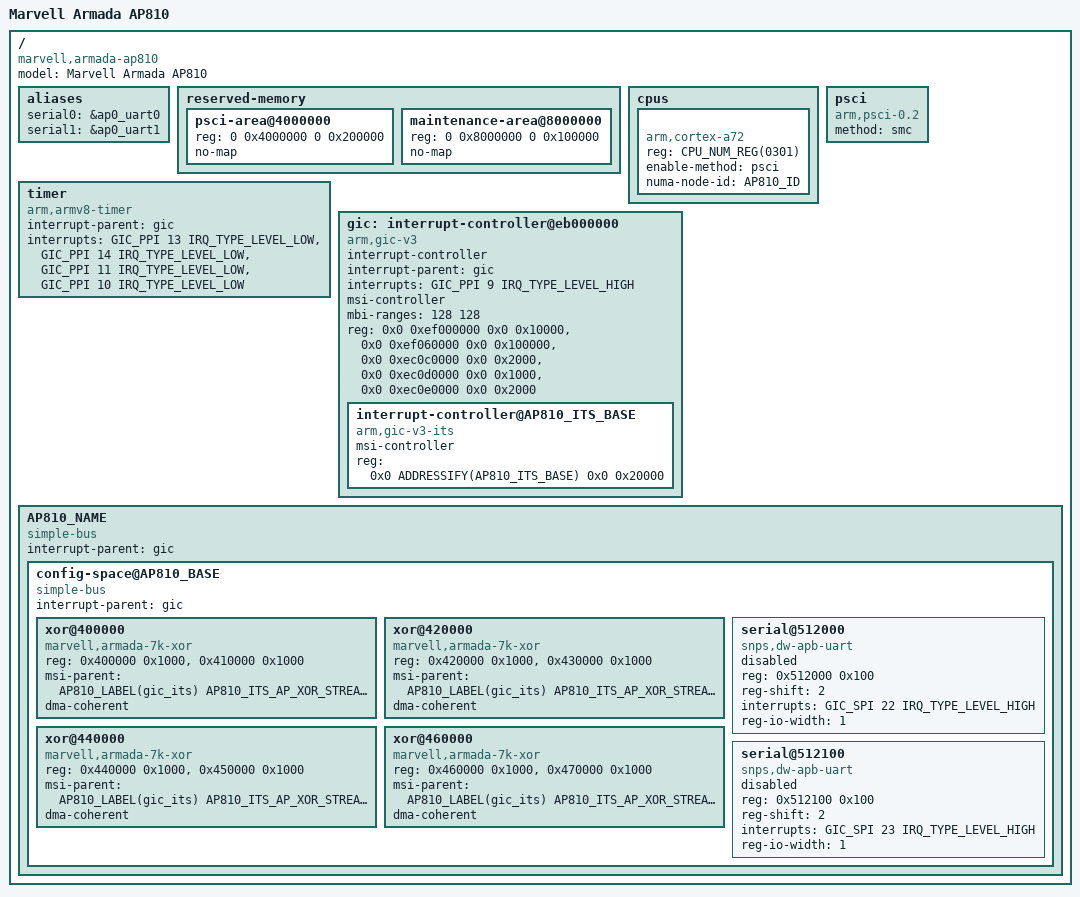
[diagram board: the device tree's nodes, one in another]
// SPDX-License-Identifier: (GPL-2.0+ OR MIT)
/*
 * Copyright (C) 2017 Marvell Technology Group Ltd.
 *
 * Device Tree file for Marvell Armada AP810.
 *
 * To include this file, the following definitions must exist:
 *  - AP810_ID:       number of the AP
 *  - AP810_NAME:     provided by armada-common.dtsi based on AP810_ID
 *  - AP810_LABEL:    provided by armada-common.dtsi based on AP810_ID
 *  - AP810_BASE:     base address of registers for this AP
 *                    (without leading 0x)
 *  - AP810_ITS_BASE: base address of the ITS for this AP
 *                    (without leading 0x)
 */

#include <dt-bindings/interrupt-controller/arm-gic.h>

#define CPU_NUM(x)	EVALUATOR(AP810_ID, x)
#define CPU_NUM_REG(x)	ADDRESSIFY(CPU_NUM(x))

#define AP810_ITS_AP_XOR_STREAM_ID(x)	(0x200 * AP810_ID + 0x100 + (x))

/ {
	model = "Marvell Armada AP810";
	compatible = "marvell,armada-ap810";
	#address-cells = <2>;
	#size-cells = <2>;

	aliases {
		serial0 = &ap0_uart0;
		serial1 = &ap0_uart1;
	};

        reserved-memory {
                #address-cells = <2>;
                #size-cells = <2>;
                ranges;

                psci-area@4000000 {
                        reg = <0 0x4000000 0 0x200000>;
                        no-map;
                };

                maintenance-area@8000000 {
                        reg = <0 0x8000000 0 0x100000>;
                        no-map;
                };
        };

	cpus {
		#address-cells = <1>;
		#size-cells = <0>;

		cpu@CPU_NUM(0000) {
			device_type = "cpu";
			compatible = "arm,cortex-a72", "arm,armv8";
			reg = <CPU_NUM_REG(0000)>;
			enable-method = "psci";
			numa-node-id = <AP810_ID>;
		};
		cpu@CPU_NUM(0001) {
			device_type = "cpu";
			compatible = "arm,cortex-a72", "arm,armv8";
			reg = <CPU_NUM_REG(0001)>;
			enable-method = "psci";
			numa-node-id = <AP810_ID>;
		};
		cpu@CPU_NUM(0100) {
			device_type = "cpu";
			compatible = "arm,cortex-a72", "arm,armv8";
			reg = <CPU_NUM_REG(0100)>;
			enable-method = "psci";
			numa-node-id = <AP810_ID>;
		};
		cpu@CPU_NUM(0101) {
			device_type = "cpu";
			compatible = "arm,cortex-a72", "arm,armv8";
			reg = <CPU_NUM_REG(0101)>;
			enable-method = "psci";
			numa-node-id = <AP810_ID>;
		};
		cpu@CPU_NUM(0200) {
			device_type = "cpu";
			compatible = "arm,cortex-a72", "arm,armv8";
			reg = <CPU_NUM_REG(0200)>;
			enable-method = "psci";
			numa-node-id = <AP810_ID>;
		};
		cpu@CPU_NUM(0201) {
			device_type = "cpu";
			compatible = "arm,cortex-a72", "arm,armv8";
			reg = <CPU_NUM_REG(0201)>;
			enable-method = "psci";
			numa-node-id = <AP810_ID>;
		};
		cpu@CPU_NUM(0300) {
			device_type = "cpu";
			compatible = "arm,cortex-a72", "arm,armv8";
			reg = <CPU_NUM_REG(0300)>;
			enable-method = "psci";
			numa-node-id = <AP810_ID>;
		};
		cpu@CPU_NUM(0301) {
			device_type = "cpu";
			compatible = "arm,cortex-a72", "arm,armv8";
			reg = <CPU_NUM_REG(0301)>;
			enable-method = "psci";
			numa-node-id = <AP810_ID>;
		};
	};

	psci {
		compatible = "arm,psci-0.2";
		method = "smc";
	};

	timer {
		compatible = "arm,armv8-timer";
		interrupt-parent = <&gic>;
		interrupts = <GIC_PPI 13 IRQ_TYPE_LEVEL_LOW>,
			     <GIC_PPI 14 IRQ_TYPE_LEVEL_LOW>,
			     <GIC_PPI 11 IRQ_TYPE_LEVEL_LOW>,
			     <GIC_PPI 10 IRQ_TYPE_LEVEL_LOW>;
	};

	gic: interrupt-controller@eb000000 {
		compatible = "arm,gic-v3";
		#interrupt-cells = <3>;
		#address-cells = <2>;
		#size-cells = <2>;
		interrupt-controller;
		interrupt-parent = <&gic>;
		interrupts = <GIC_PPI 9 IRQ_TYPE_LEVEL_HIGH>;
		msi-controller;
		mbi-ranges = <128 128>; /* FIXME */
		ranges;

		reg = <0x0 0xef000000 0x0 0x10000>,	/* GICD */
		      <0x0 0xef060000 0x0 0x100000>,	/* GICR */
		      <0x0 0xec0c0000 0x0 0x2000>,	/* GICC */
		      <0x0 0xec0d0000 0x0 0x1000>,	/* GICH */
		      <0x0 0xec0e0000 0x0 0x2000>;	/* GICV */

		AP810_LABEL(gic_its): interrupt-controller@AP810_ITS_BASE {
			compatible = "arm,gic-v3-its";
			msi-controller;
			#msi-cells = <1>;
			reg = <0x0 ADDRESSIFY(AP810_ITS_BASE) 0x0 0x20000>;
		};
	};

	AP810_NAME {
		#address-cells = <2>;
		#size-cells = <2>;
		compatible = "simple-bus";
		interrupt-parent = <&gic>;
		ranges;

		config-space@AP810_BASE {
			#address-cells = <1>;
			#size-cells = <1>;
			compatible = "simple-bus";
			ranges = <0x0 0x0 ADDRESSIFY(AP810_BASE) 0x4000000>;
			interrupt-parent = <&gic>;

			AP810_LABEL(xor0): xor@400000 {
				compatible = "marvell,armada-7k-xor", "marvell,xor-v2";
				reg = <0x400000 0x1000>,
				      <0x410000 0x1000>;
				msi-parent = <&AP810_LABEL(gic_its) AP810_ITS_AP_XOR_STREAM_ID(0)>;
				dma-coherent;
			};

			AP810_LABEL(xor1): xor@420000 {
				compatible = "marvell,armada-7k-xor", "marvell,xor-v2";
				reg = <0x420000 0x1000>,
				      <0x430000 0x1000>;
				msi-parent = <&AP810_LABEL(gic_its) AP810_ITS_AP_XOR_STREAM_ID(1)>;
				dma-coherent;
			};

			AP810_LABEL(xor2): xor@440000 {
				compatible = "marvell,armada-7k-xor", "marvell,xor-v2";
				reg = <0x440000 0x1000>,
				      <0x450000 0x1000>;
				msi-parent = <&AP810_LABEL(gic_its) AP810_ITS_AP_XOR_STREAM_ID(2)>;
				dma-coherent;
			};

			AP810_LABEL(xor3): xor@460000 {
				compatible = "marvell,armada-7k-xor", "marvell,xor-v2";
				reg = <0x460000 0x1000>,
				      <0x470000 0x1000>;
				msi-parent = <&AP810_LABEL(gic_its) AP810_ITS_AP_XOR_STREAM_ID(3)>;
				dma-coherent;
			};

			AP810_LABEL(uart0): serial@512000 {
				compatible = "snps,dw-apb-uart";
				reg = <0x512000 0x100>;
				reg-shift = <2>;
				interrupts = <GIC_SPI 22 IRQ_TYPE_LEVEL_HIGH>;
				reg-io-width = <1>;
				status = "disabled";
			};

			AP810_LABEL(uart1): serial@512100 {
				compatible = "snps,dw-apb-uart";
				reg = <0x512100 0x100>;
				reg-shift = <2>;
				interrupts = <GIC_SPI 23 IRQ_TYPE_LEVEL_HIGH>;
				reg-io-width = <1>;
				status = "disabled";
			};
		};
	};
};
